# LPC2103 register map
Series: LPC2000; File version: r4p0
LPC2103 is a ARM7TDMI based microcontroller.
CPU: other r0p0, selectable endian, no FPU, vendor SysTick, 2 interrupt priority bits
Registers are read-write, reset 0x0 unless marked. A register's access mark holds for its fields unless they carry their own. Offsets are from the block's base; lines under a group give offsets from that group; [hi:lo] are bit positions; {n}, {i} and the like mark numbered series; 'fields as' and 'values as' point back to an identical list; <NAME> marks a mode.

## Memory map
0x3FFFC000 FIO0 blocks up to offset 0x20 — Fast General Purpose I/O
0xE0000000 WDT size 0x10 — Watchdog Timer
0xE0004000 TIMER0 blocks up to offset 0x78 — General Purpose Timer 0
0xE0008000 TIMER1 blocks up to offset 0x78 — General Purpose Timer 1
0xE000C000 UART0 blocks up to offset 0x34 — Universial Asynchronous Receiver/Transceiver
0xE0010000 UART1 blocks up to offset 0x34
0xE001C000 I2C0 size 0x1C
0xE0020000 SPI blocks up to offset 0x20 — Serial Peripheral Interface
0xE0024000 RTC blocks up to offset 0x88 — Real-time Clock
0xE0028000 GPIO0 size 0x10 — General Purpose I/O
0xE002C000 PCB size 0x8 — Pin Connect Block
0xE0034000 ADC blocks up to offset 0x34 — Analog-to-Digital Converter
0xE005C000 I2C1 size 0x1C
0xE0068000 SSP size 0x24 — Synchronous Serial Port
0xE0070000 TIMER2 blocks up to offset 0x78 — General Purpose Timer 2
0xE0074000 TIMER3 blocks up to offset 0x78 — General Purpose Timer 3
0xE01FC000 SYS blocks up to offset 0x1A4 — Memory Acceleration Module
0xFFFFF000 VIC blocks up to offset 0x240 — Vectored Interrupt Controller

## Interrupts
0 WDT
1 SOFT_IRQ (VIC) — Soft Interrupt
2 CPURX (VIC) — CPU Debug RX
3 CPUTX (VIC) — CPU Debug TX
4 TIMER0
5 TIMER1
6 UART0
7 UART1
9 I2C0
10 SPI
11 SSP
12 PLL (SYS) — PLL State Change
13 RTC
14 EINT0 (SYS) — External Interrupt 0
15 EINT1 (SYS) — External Interrupt 1
16 EINT2 (SYS) — External Interrupt 2
18 ADC
19 I2C1
26 TIMER2
27 TIMER3

## SYS — Memory Acceleration Module
Base 0xE01FC000
0x00 MAM group — Memory Accemeration Module
  0x00 CR — Control Register
    [1:0] MODE_CONTROL
      0=DISABLED; 1=PARTIAL; 2=ENABLED
  0x04 TIM reset 0x7 — Timing Register
    [2:0] FETCH_CYCLE range 1..7
0x40 MEMMAP — Memory Map Register
  [1:0] MAP
    0=BOOTLOADER (Bootloader memory mapped to interrupt vector.); 1=FLASH (Flash memory mapped to interrupt vector.); 2=SRAM (SRAM mapped to interrupt vector.)
0x80 PLL group — Phased Lock Loop
  0x00 CON — Control Register
    [1] PLLC — PLL Connect
      0=XTAL (Core clocked through XTAL); 1=PLL (Core clocked through PLL)
    [0] PLLE — PLL Enable
      0=DISABLED; 1=ENABLED
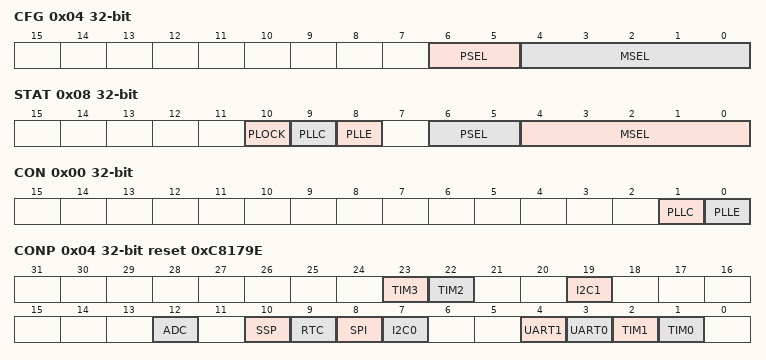
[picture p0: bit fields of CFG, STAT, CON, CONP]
  0x04 CFG — Configuration Register
    [6:5] PSEL — PLL Divider Selection
      0=DIV1; 1=DIV2; 2=DIV4; 3=DIV8
    [4:0] MSEL — PLL Multiplier
  0x08 STAT ro — Status Register
    [10] PLOCK — PLL Locked
      0=UNLOCKED (PLL have not locked.); 1=LOCKED (PLL have locked.)
    [9] PLLC — PLL Connect
      values as PLL.CON.PLLC
    [8] PLLE — PLL Enable
      0=DISABLED; 1=ENABLED
    [6:5] PSEL — PLL Divider Selection
      0=DIV1; 1=DIV2; 2=DIV4; 3=DIV8
    [4:0] MSEL — PLL Multiplier
  0x0C FEED wo
    [7:0] FEED
      170=KEY1; 85=KEY2
0xC0 PWR group — Power Control
  0x00 CON — Processor Power Control
    [1] PD — Power down the microcontroller.
    [0] IDL — Stop processor until an interrupt comes in.
  0x04 CONP reset 0xC8179E — Peripheral Power Control
    [23] TIM3, [22] TIM2, [19] I2C1, [12] ADC, [10] SSP, [9] RTC, [8] SPI, [7] I2C0, [4] UART1, [3] UART0, [2] TIM1, [1] TIM0
0x100 APBDIV — APB Divider
  [1:0] DIV
    0=DIV4; 1=DIV1; 2=DIV2
0x140 EINT group — External Interrupts
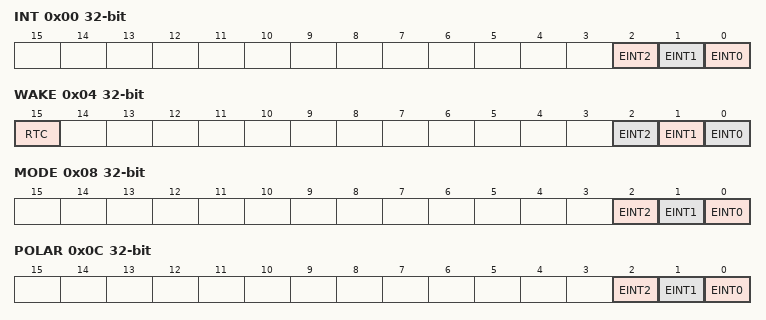
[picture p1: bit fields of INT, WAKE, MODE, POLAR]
  0x00 INT write-1-clears — Interrupt Register
    [2] EINT2, [1] EINT1, [0] EINT0
  0x04 WAKE — Wakeup Register
    [15] RTC, [2] EINT2, [1] EINT1, [0] EINT0
  0x08 MODE — Interrupe Mode Register
    [all] fields
      0=LEVEL (Interrupt is level-sensitive.); 1=EDGE (Interrupt is edge-sensitive.)
    [2] EINT2
    [1] EINT1
    [0] EINT0
  0x0C POLAR — Interrupt Polarity Register
    [all] fields
      0=LOW (Interrupt triggers on LOW level.); 1=HIGH (Interrupt triggers on HIGH level.)
    [2] EINT2
    [1] EINT1
    [0] EINT0
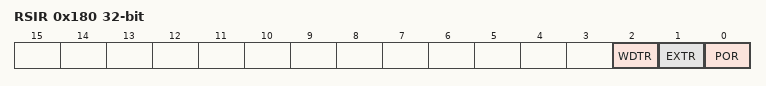
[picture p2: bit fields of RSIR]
0x180 RSIR write-1-clears — Reset Reason Register
  [2] WDTR, [1] EXTR, [0] POR
0x184 CSPR ro — Code Security Protection Register
0x1A0 SCS — System Control and Status Register
  [0] GPIO0M — GPIO0 High-speed Access
    0=DISABLED; 1=ENABLED
